# CY8C5868AXI_LP035 register map
File version: 0.1
CY8C58LP
Registers are 8-bit, read-write, no defined reset value unless marked. A register's access mark holds for its fields unless they carry their own. Offsets are from the block's base; lines under a group give offsets from that group; [hi:lo] are bit positions; {n}, {i} and the like mark numbered series; 'fields as' and 'values as' point back to an identical list; <NAME> marks a mode.

## Memory map
0x00000000 Packet_Uart — UART
0x00000000 Cursor_Update_Timer
0x00000000 USBUART — USBFS
0x00000000 tx_sender
0x00000000 LED_Update_Timer
0x40006472 CBA_Row
0x40006575 RGB_2
0x40006576 RGB_1
0x4000657B tx_packet_allow

## Packet_Uart — UART
Base 0x00000000
0x40006423 RX_Packet_Uart_RX_ADDRESS1 — RX Address1 Register
0x40006433 RX_Packet_Uart_RX_ADDRESS2 — RX Address2 Register
0x40006443 RX_Packet_Uart_RX_DATA — RX Data Register
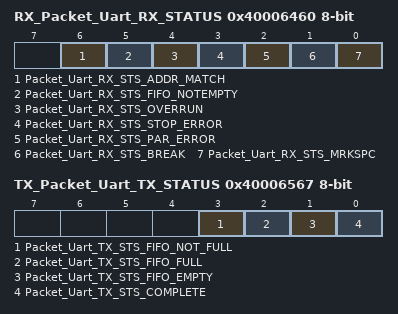
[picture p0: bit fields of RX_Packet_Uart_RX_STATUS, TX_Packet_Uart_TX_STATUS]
0x40006460 RX_Packet_Uart_RX_STATUS — RX status register
  [6] Packet_Uart_RX_STS_ADDR_MATCH ro, [5] Packet_Uart_RX_STS_FIFO_NOTEMPTY ro, [4] Packet_Uart_RX_STS_OVERRUN ro, [3] Packet_Uart_RX_STS_STOP_ERROR ro, [2] Packet_Uart_RX_STS_PAR_ERROR ro, [1] Packet_Uart_RX_STS_BREAK ro, [0] Packet_Uart_RX_STS_MRKSPC ro
0x40006547 TX_Packet_Uart_TX_DATA — TX Data Register
0x40006567 TX_Packet_Uart_TX_STATUS — TX status register
  [3] Packet_Uart_TX_STS_FIFO_NOT_FULL ro, [2] Packet_Uart_TX_STS_FIFO_FULL ro, [1] Packet_Uart_TX_STS_FIFO_EMPTY ro, [0] Packet_Uart_TX_STS_COMPLETE ro

## Cursor_Update_Timer
Base 0x00000000
0x40006504 Cursor_Update_Timer_COUNTER 16-bit — UDB.A0 - Current Down Counter Value
0x40006524 Cursor_Update_Timer_PERIOD 16-bit — UDB.D0 - Assigned Period
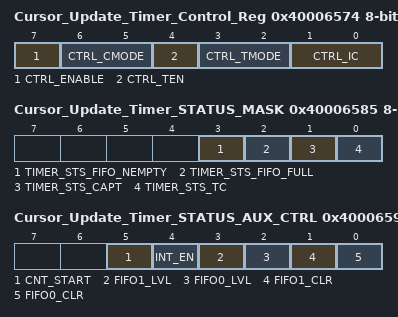
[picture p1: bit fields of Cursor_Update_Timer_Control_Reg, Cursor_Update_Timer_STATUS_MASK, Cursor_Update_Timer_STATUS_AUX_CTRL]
0x40006574 Cursor_Update_Timer_Control_Reg — UDB Control Register - Assigned Control Register Value
  [7] CTRL_ENABLE — Enable the Timer
  [6:5] CTRL_CMODE — Capture Mode
  [4] CTRL_TEN — Trigger Enable Bit
  [3:2] CTRL_TMODE — Trigger Mode
  [1:0] CTRL_IC — Interrupt Count
0x40006585 Cursor_Update_Timer_STATUS_MASK — UDB Status bits Interrupt Mask Enable Register
  [3] TIMER_STS_FIFO_NEMPTY ro — FIFO Empty status
  [2] TIMER_STS_FIFO_FULL ro — FIFO Full Status
  [1] TIMER_STS_CAPT ro — Enables the Interrupt on Capture
  [0] TIMER_STS_TC ro — Enables the Interrupt on TC
0x40006595 Cursor_Update_Timer_STATUS_AUX_CTRL — UDB Auxilliary Control Register
  [5] CNT_START — FIFO0 clear
    0=E_CNT_START0 (Disable counter); 1=E_CNT_START1 (Enable counter)
  [4] INT_EN
    0=E_INT_EN0 (Interrupt disabled); 1=E_INT_EN1 (Interrupt enabled)
  [3] FIFO1_LVL — FIFO level
    0=E_FIFO_LVL_0 (FIFO LVL: input mode: FIFO not full; output mode: FIFO not empty); 1=E_FIFO_LVL_1 (FIFO LVL: input mode: FIFO at least 1/2 empty; output mode: FIFO at least 1/2 full)
  [2] FIFO0_LVL — FIFO level
    values as FIFO1_LVL
  [1] FIFO1_CLR — FIFO1 clear
    0=E_FIFO_CLR_0 (Normal FIFO operation); 1=E_FIFO_CLR_1 (Clear FIFO state)
  [0] FIFO0_CLR — FIFO0 clear
    values as FIFO1_CLR

## tx_packet_allow
Base 0x4000657B
0x00 tx_packet_allow_CONTROL_REG

## RGB_2
Base 0x40006575
Registers as tx_packet_allow (with tx_packet_allow read as RGB_2).

## CBA_Row
Base 0x40006472
Registers as tx_packet_allow (with tx_packet_allow read as CBA_Row).

## RGB_1
Base 0x40006576
Registers as tx_packet_allow (with tx_packet_allow read as RGB_1).

## tx_sender
Base 0x00000000
0x40006404 tx_sender_COUNTER 24-bit — UDB.A0 - Current Down Counter Value
0x40006424 tx_sender_PERIOD 24-bit — UDB.D0 - Assigned Period
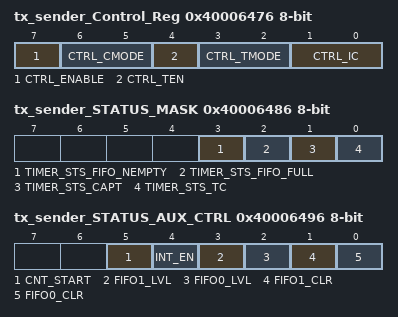
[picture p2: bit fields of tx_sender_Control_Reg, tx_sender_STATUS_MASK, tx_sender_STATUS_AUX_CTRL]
0x40006476 tx_sender_Control_Reg — UDB Control Register - Assigned Control Register Value
  [7] CTRL_ENABLE — Enable the Timer
  [6:5] CTRL_CMODE — Capture Mode
  [4] CTRL_TEN — Trigger Enable Bit
  [3:2] CTRL_TMODE — Trigger Mode
  [1:0] CTRL_IC — Interrupt Count
0x40006486 tx_sender_STATUS_MASK — UDB Status bits Interrupt Mask Enable Register
  [3] TIMER_STS_FIFO_NEMPTY ro — FIFO Empty status
  [2] TIMER_STS_FIFO_FULL ro — FIFO Full Status
  [1] TIMER_STS_CAPT ro — Enables the Interrupt on Capture
  [0] TIMER_STS_TC ro — Enables the Interrupt on TC
0x40006496 tx_sender_STATUS_AUX_CTRL — UDB Auxilliary Control Register
  [5] CNT_START — FIFO0 clear
    0=E_CNT_START0 (Disable counter); 1=E_CNT_START1 (Enable counter)
  [4] INT_EN
    0=E_INT_EN0 (Interrupt disabled); 1=E_INT_EN1 (Interrupt enabled)
  [3] FIFO1_LVL — FIFO level
    0=E_FIFO_LVL_0 (FIFO LVL: input mode: FIFO not full; output mode: FIFO not empty); 1=E_FIFO_LVL_1 (FIFO LVL: input mode: FIFO at least 1/2 empty; output mode: FIFO at least 1/2 full)
  [2] FIFO0_LVL — FIFO level
    values as FIFO1_LVL
  [1] FIFO1_CLR — FIFO1 clear
    0=E_FIFO_CLR_0 (Normal FIFO operation); 1=E_FIFO_CLR_1 (Clear FIFO state)
  [0] FIFO0_CLR — FIFO0 clear
    values as FIFO1_CLR
